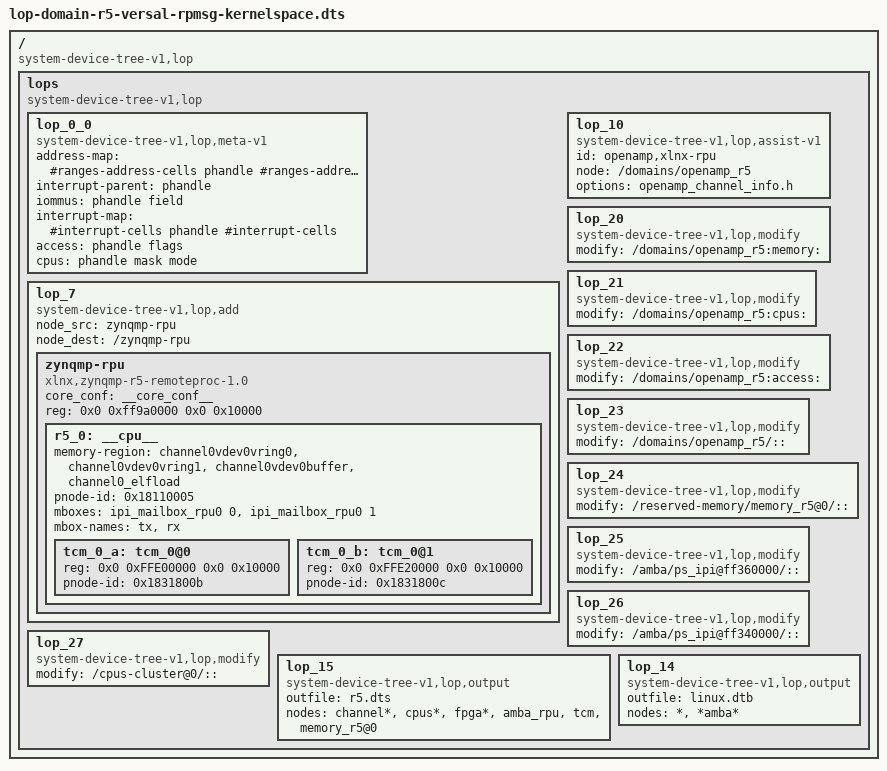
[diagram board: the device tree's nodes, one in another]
/*
ps/lop-domain-r5-versal-rpmsg-kernelspace.dts
 * Copyright (c) 2019,2020 Xilinx Inc. All rights reserved.
 *
 * Author:
 *       Bruce Ashfield <bruce.ashfield@xilinx.com>
 *
 * SPDX-License-Identifier: BSD-3-Clause
 */

/dts-v1/;

/ {
        compatible = "system-device-tree-v1,lop";
        lops {
                compatible = "system-device-tree-v1,lop";
                lop_0_0 {
                        compatible = "system-device-tree-v1,lop,meta-v1","phandle-desc-v1";
                        address-map = "#ranges-address-cells phandle #ranges-address-cells #ranges-size-cells";
                        interrupt-parent = "phandle";
                        iommus = "phandle field";
                        interrupt-map = "#interrupt-cells phandle #interrupt-cells";
                        access = "phandle flags";
                        cpus = "phandle mask mode";
                };

                lop_7 {
                        // node add
                        compatible = "system-device-tree-v1,lop,add";
                        node_src = "zynqmp-rpu";
                        node_dest = "/zynqmp-rpu";
                        zynqmp-rpu {
                            compatible = "xlnx,zynqmp-r5-remoteproc-1.0";
                            #address-cells = <2>;
                            #size-cells = <2>;
                            ranges;
                            core_conf = "__core_conf__";
			    reg = <0x0 0xff9a0000 0x0 0x10000>;
                            r5_0: __cpu__ {
                                  #address-cells = <2>;
                                  #size-cells = <2>;
                                  ranges;
                                  memory-region = <&channel0vdev0vring0>, <&channel0vdev0vring1>, <&channel0vdev0buffer>, <&channel0_elfload> ;
                                  pnode-id = <0x18110005>;
                                  mboxes = <&ipi_mailbox_rpu0 0>, <&ipi_mailbox_rpu0 1>;
                                  mbox-names = "tx", "rx";
                                  tcm_0_a: tcm_0@0 {
                                           reg = <0x0 0xFFE00000 0x0 0x10000>;
                                           pnode-id = <0x1831800b>;
                                  };
                                  tcm_0_b: tcm_0@1 {
                                         reg = <0x0 0xFFE20000 0x0 0x10000>;
                                         pnode-id = <0x1831800c>;
                                  };
                            };
                        };
                  };
                  lop_10 {
                          // optionally execute a routine in a loaded module. If the routine
                          // isn't found, this is NOT a failure. Since we don't want to tightly
                          // couple these transforms and loaded modules
                          compatible = "system-device-tree-v1,lop,assist-v1";
                          id = "openamp,xlnx-rpu";
                          node = "/domains/openamp_r5";
                          options = "openamp_channel_info.h";
                  };
                  lop_20 {
                        compatible = "system-device-tree-v1,lop,modify";
                        modify = "/domains/openamp_r5:memory:";

                  };
                  lop_21 {
                        compatible = "system-device-tree-v1,lop,modify";
                        modify = "/domains/openamp_r5:cpus:";

                  };
                  lop_22 {
                        compatible = "system-device-tree-v1,lop,modify";
                        modify = "/domains/openamp_r5:access:";

                  };
                  lop_23 {
                        compatible = "system-device-tree-v1,lop,modify";
                        modify = "/domains/openamp_r5/::";

                  };
                  lop_24 {
                        compatible = "system-device-tree-v1,lop,modify";
                        modify = "/reserved-memory/memory_r5@0/::";

                  };
                  lop_25 {
                        compatible = "system-device-tree-v1,lop,modify";
                        modify = "/amba/ps_ipi@ff360000/::";

                  };
                  lop_26 {
                        compatible = "system-device-tree-v1,lop,modify";
                        modify = "/amba/ps_ipi@ff340000/::";

                  };
		  lop_27 {
			 compatible = "system-device-tree-v1,lop,modify";
			  modify = "/cpus-cluster@0/::";
		  };

                  lop_15 {
                         compatible = "system-device-tree-v1,lop,output";
                         outfile = "r5.dts";
                         // * is "all nodes"
                         nodes = "channel*", "cpus*","fpga*", "amba_rpu","tcm","memory_r5@0";
                  };
                  lop_14 {
                         compatible = "system-device-tree-v1,lop,output";
                         outfile = "linux.dtb";
                         // * is "all nodes"
			 nodes =  "*", "*amba*";
                  };

        };
};
